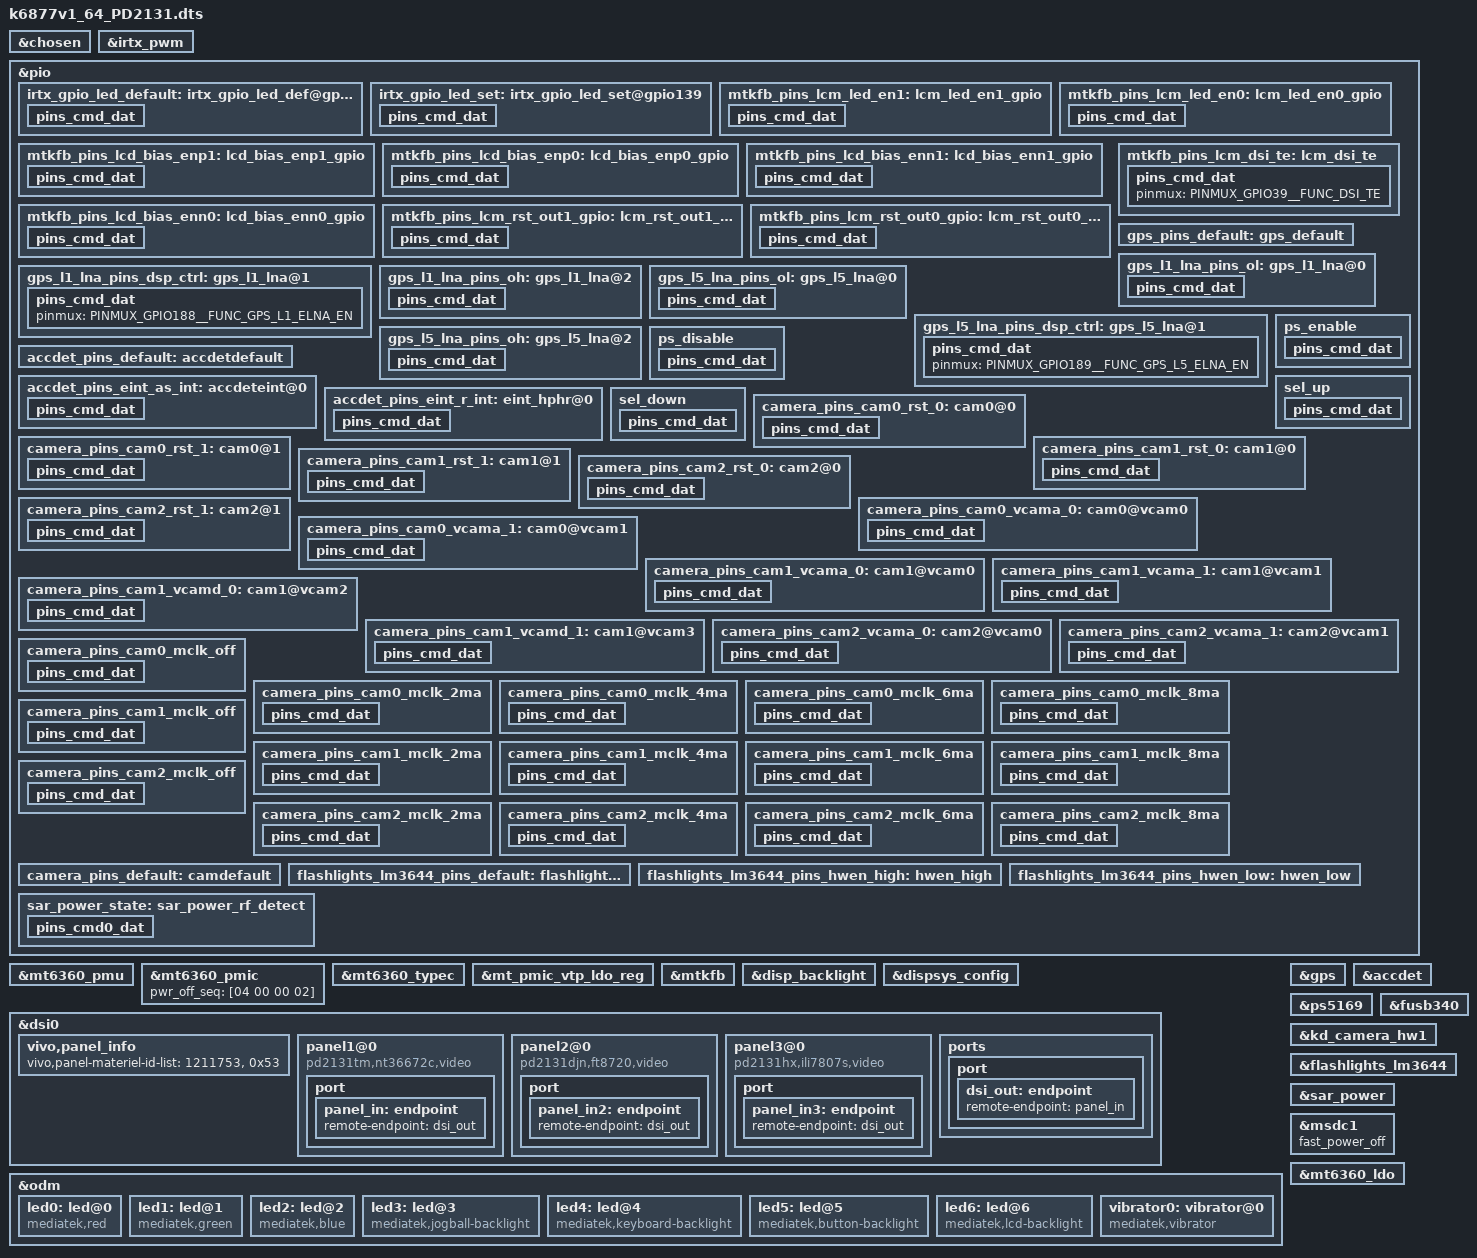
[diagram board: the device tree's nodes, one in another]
/*
 * Mediatek's mt6853 SoC device tree source
 *
 * Copyright (C) 2016 MediaTek Inc.
 *
 * This program is free software; you can redistribute it and/or modify
 * it under the terms of the GNU General Public License version 2 as
 * published by the Free Software Foundation.
 *
 * This program is distributed in the hope that it will be useful,
 * but WITHOUT ANY WARRANTY; without even the implied warranty of
 * MERCHANTABILITY or FITNESS FOR A PARTICULAR PURPOSE.
 * See http://www.gnu.org/licenses/gpl-2.0.html for more details.
 */
/dts-v1/;
/plugin/;
#include <generated/autoconf.h>
#include <dt-bindings/interrupt-controller/irq.h>
#include <dt-bindings/interrupt-controller/arm-gic.h>
#include <dt-bindings/pinctrl/mt6877-pinfunc.h>

/* chosen */
&chosen {
	atag,videolfb-fb_base_l = <0x7e605000>;
	atag,videolfb-fb_base_h = <0x0>;
	atag,videolfb-islcmfound = <1>;
	atag,videolfb-islcm_inited = <0>;
	atag,videolfb-fps= <6000>;
	atag,videolfb-vramSize= <0x1be0000>;
	atag,videolfb-lcmname=
		"td4330_fhdp_dsi_cmd_auo_rt4831_drv";
	atag,videolfb-project-name= "PD2131";
	atag,vivo-dsi-panel-type = "super_tft";
	atag,exception-event-support;
	default-backlight-level = <1146>;
	20ma-brightness-typical-val = <2045>;
	lcd-hbm-support = <1>;
	bias-ic-use-i2c = <3>;
	bl-ic-use-i2c = <3>;
};

/* IRTX GPIO Start */
&irtx_pwm {
	pinctrl-names = "irtx_gpio_led_default", "irtx_gpio_led_set";
	pinctrl-0 = <&irtx_gpio_led_default>;
	pinctrl-1 = <&irtx_gpio_led_set>;
	status = "okay";
};
&pio {
	/* IRTX GPIO Settings -Start */
	/* default: GPIO0, output, high */
	irtx_gpio_led_default:irtx_gpio_led_def@gpio139 {
		pins_cmd_dat {
			pinmux = <PINMUX_GPIO139__FUNC_GPIO139>;
			slew-rate = <1>;
			bias-disable;
			output-low;
			input-schmitt-enable = <0>;
		};
	};

	irtx_gpio_led_set:irtx_gpio_led_set@gpio139 {
		pins_cmd_dat {
			pinmux = <PINMUX_GPIO139__FUNC_PWM_1>;
			slew-rate = <1>;
			output-high;
		};
	};
}; /* IRTX GPIO Settings -End */

&mt6360_pmu {
	mt6360,intr_gpio_num = <4>; /* direct defined GPIO num */
	mt6360,intr_gpio = <&pio 4 0x0>;
};

&mt6360_pmic {
	pwr_off_seq = [04 00 00 02];
};

&mt6360_typec {
	mt6360pd,intr_gpio_num = <5>; /* direct defined GPIO num */
	mt6360pd,intr_gpio = <&pio 5 0x0>;
};

/* add by sensor team for Psensor LED LDO2*/
&mt_pmic_vtp_ldo_reg {
	regulator-min-microvolt = <3000000>;
	regulator-max-microvolt = <3000000>;
	regulator-always-on;
};

&pio {
	mtkfb_pins_lcm_led_en1: lcm_led_en1_gpio {
		pins_cmd_dat {
			pinmux = <PINMUX_GPIO139__FUNC_GPIO139>;
			slew-rate = <1>;
			output-high;
		};
	};

	mtkfb_pins_lcm_led_en0: lcm_led_en0_gpio {
		pins_cmd_dat {
			pinmux = <PINMUX_GPIO139__FUNC_GPIO139>;
			slew-rate = <1>;
			output-low;
		};
	};

	mtkfb_pins_lcd_bias_enp1: lcd_bias_enp1_gpio {
		pins_cmd_dat {
			pinmux = <PINMUX_GPIO141__FUNC_GPIO141>;
			slew-rate = <1>;
			output-high;
		};
	};

	mtkfb_pins_lcd_bias_enp0: lcd_bias_enp0_gpio {
		pins_cmd_dat {
			pinmux = <PINMUX_GPIO141__FUNC_GPIO141>;
			slew-rate = <1>;
			output-low;
		};
	};

	mtkfb_pins_lcd_bias_enn1: lcd_bias_enn1_gpio {
		pins_cmd_dat {
			pinmux = <PINMUX_GPIO140__FUNC_GPIO140>;
			slew-rate = <1>;
			output-high;
		};
	};

	mtkfb_pins_lcd_bias_enn0: lcd_bias_enn0_gpio {
		pins_cmd_dat {
			pinmux = <PINMUX_GPIO140__FUNC_GPIO140>;
			slew-rate = <1>;
			output-low;
		};
	};

	mtkfb_pins_lcm_rst_out1_gpio: lcm_rst_out1_gpio {
		pins_cmd_dat {
			pinmux = <PINMUX_GPIO40__FUNC_GPIO40>;
			slew-rate = <1>;
			output-high;
		};
	};

	mtkfb_pins_lcm_rst_out0_gpio: lcm_rst_out0_gpio {
		pins_cmd_dat {
			pinmux = <PINMUX_GPIO40__FUNC_GPIO40>;
			slew-rate = <1>;
			output-low;
		};
	};
	mtkfb_pins_lcm_dsi_te: lcm_dsi_te {
		pins_cmd_dat {
			pinmux = <PINMUX_GPIO39__FUNC_DSI_TE>;
		};
	};
};

&mtkfb {
	pinctrl-names = "lcm_led_en1_gpio", "lcm_led_en0_gpio",
		"lcd_bias_enp1_gpio", "lcd_bias_enp0_gpio",
		"lcd_bias_enn1_gpio", "lcd_bias_enn0_gpio",
		"lcm_rst_out1_gpio", "lcm_rst_out0_gpio",
		"mode_te_te";
	pinctrl-0 = <&mtkfb_pins_lcm_led_en1>;
	pinctrl-1 = <&mtkfb_pins_lcm_led_en0>;
	pinctrl-2 = <&mtkfb_pins_lcd_bias_enp1>;
	pinctrl-3 = <&mtkfb_pins_lcd_bias_enp0>;
	pinctrl-4 = <&mtkfb_pins_lcd_bias_enn1>;
	pinctrl-5 = <&mtkfb_pins_lcd_bias_enn0>;
	pinctrl-6 = <&mtkfb_pins_lcm_rst_out1_gpio>;
	pinctrl-7 = <&mtkfb_pins_lcm_rst_out0_gpio>;
	pinctrl-8 = <&mtkfb_pins_lcm_dsi_te>;
	status = "okay";
};

&disp_backlight {
	max-brightness = <2047>;
	led-bits = <11>;
};

&dispsys_config {
	pinctrl-names =
		"lcm_rst_out1_gpio", "lcm_rst_out0_gpio",
		"mode_te_te";
	pinctrl-0 = <&mtkfb_pins_lcm_rst_out1_gpio>;
	pinctrl-1 = <&mtkfb_pins_lcm_rst_out0_gpio>;
	pinctrl-2 = <&mtkfb_pins_lcm_dsi_te>;
	status = "okay";

	helper-name = "MTK_DRM_OPT_STAGE",
		"MTK_DRM_OPT_USE_CMDQ",
		"MTK_DRM_OPT_USE_M4U",
		"MTK_DRM_OPT_SODI_SUPPORT",
		"MTK_DRM_OPT_IDLE_MGR",
		"MTK_DRM_OPT_IDLEMGR_SWTCH_DECOUPLE",
		"MTK_DRM_OPT_IDLEMGR_BY_REPAINT",
		"MTK_DRM_OPT_IDLEMGR_ENTER_ULPS",
		"MTK_DRM_OPT_IDLEMGR_KEEP_LP11",
		"MTK_DRM_OPT_DYNAMIC_RDMA_GOLDEN_SETTING",
		"MTK_DRM_OPT_IDLEMGR_DISABLE_ROUTINE_IRQ",
		"MTK_DRM_OPT_MET_LOG",
		"MTK_DRM_OPT_USE_PQ",
		"MTK_DRM_OPT_ESD_CHECK_RECOVERY",
		"MTK_DRM_OPT_ESD_CHECK_SWITCH",
		"MTK_DRM_OPT_PRESENT_FENCE",
		"MTK_DRM_OPT_RDMA_UNDERFLOW_AEE",
		"MTK_DRM_OPT_DSI_UNDERRUN_AEE",
		"MTK_DRM_OPT_HRT",
		"MTK_DRM_OPT_HRT_MODE",
		"MTK_DRM_OPT_DELAYED_TRIGGER",
		"MTK_DRM_OPT_OVL_EXT_LAYER",
		"MTK_DRM_OPT_AOD",
		"MTK_DRM_OPT_RPO",
		"MTK_DRM_OPT_DUAL_PIPE",
		"MTK_DRM_OPT_DC_BY_HRT",
		"MTK_DRM_OPT_OVL_WCG",
		"MTK_DRM_OPT_OVL_SBCH",
		"MTK_DRM_OPT_COMMIT_NO_WAIT_VBLANK",
		"MTK_DRM_OPT_MET",
		"MTK_DRM_OPT_REG_PARSER_RAW_DUMP",
		"MTK_DRM_OPT_VP_PQ",
		"MTK_DRM_OPT_GAME_PQ",
		"MTK_DRM_OPT_MMPATH",
		"MTK_DRM_OPT_HBM",
		"MTK_DRM_OPT_VDS_PATH_SWITCH",
		"MTK_DRM_OPT_LAYER_REC",
		"MTK_DRM_OPT_CLEAR_LAYER",
		"MTK_DRM_OPT_LFR",
		"MTK_DRM_OPT_DYN_MIPI_CHANGE",
		"MTK_DRM_OPT_SF_PF";

		helper-value = <0>, /*MTK_DRM_OPT_STAGE*/
			<1>, /*MTK_DRM_OPT_USE_CMDQ*/
			<1>, /*MTK_DRM_OPT_USE_M4U*/
			<0>, /*MTK_DRM_OPT_SODI_SUPPORT*/
			<1>, /*MTK_DRM_OPT_IDLE_MGR*/
			<0>, /*MTK_DRM_OPT_IDLEMGR_SWTCH_DECOUPLE*/
			<1>, /*MTK_DRM_OPT_IDLEMGR_BY_REPAINT*/
			<0>, /*MTK_DRM_OPT_IDLEMGR_ENTER_ULPS*/
			<0>, /*MTK_DRM_OPT_IDLEMGR_KEEP_LP11*/
			<0>, /*MTK_DRM_OPT_DYNAMIC_RDMA_GOLDEN_SETTING*/
			<1>, /*MTK_DRM_OPT_IDLEMGR_DISABLE_ROUTINE_IRQ*/
			<0>, /*MTK_DRM_OPT_MET_LOG*/
			<1>, /*MTK_DRM_OPT_USE_PQ*/
			<1>, /*MTK_DRM_OPT_ESD_CHECK_RECOVERY*/
			<1>, /*MTK_DRM_OPT_ESD_CHECK_SWITCH*/
			<1>, /*MTK_DRM_OPT_PRESENT_FENCE*/
			<1>, /*MTK_DRM_OPT_RDMA_UNDERFLOW_AEE*/
			<1>, /*MTK_DRM_OPT_DSI_UNDERRUN_AEE*/
			<1>, /*MTK_DRM_OPT_HRT*/
			<1>, /*MTK_DRM_OPT_HRT_MODE*/
			<0>, /*MTK_DRM_OPT_DELAYED_TRIGGER*/
			<1>, /*MTK_DRM_OPT_OVL_EXT_LAYER*/
			<0>, /*MTK_DRM_OPT_AOD*/
			<1>, /*MTK_DRM_OPT_RPO*/
			<0>, /*MTK_DRM_OPT_DUAL_PIPE*/
			<0>, /*MTK_DRM_OPT_DC_BY_HRT*/
			<0>, /*MTK_DRM_OPT_OVL_WCG*/
			<0>, /*MTK_DRM_OPT_OVL_SBCH*/
			<1>, /*MTK_DRM_OPT_COMMIT_NO_WAIT_VBLANK*/
			<0>, /*MTK_DRM_OPT_MET*/
			<0>, /*MTK_DRM_OPT_REG_PARSER_RAW_DUMP*/
			<0>, /*MTK_DRM_OPT_VP_PQ*/
			<0>, /*MTK_DRM_OPT_GAME_PQ*/
			<0>, /*MTK_DRM_OPT_MMPATH*/
			<1>, /*MTK_DRM_OPT_HBM*/
			<0>, /*MTK_DRM_OPT_VDS_PATH_SWITCH*/
			<0>, /*MTK_DRM_OPT_LAYER_REC*/
			<1>, /*MTK_DRM_OPT_CLEAR_LAYER*/
			<0>, /*MTK_DRM_OPT_LFR*/
			<1>, /*MTK_DRM_OPT_DYN_MIPI_CHANGE*/
			<1>; /*MTK_DRM_OPT_SF_PF*/
	};

&dsi0 {
	status = "okay";
	#address-cells = <1>;
	#size-cells = <0>;

	/* vivo panel materiel info start */
	vivo,panel_info {
		/*
		 * No add new id until you have import driver for new panel ok!!!!!!
		 * vivo,panel-materiel-id-list = "materiel_id1", "lcm1_sf_id1 lcm1_sf_id2 lcm1_sf_id3...",
		 *				 "materiel_id2", "lcm2_sf_id1 lcm2_sf_id2 lcm2_sf_id3...",
		 *				 ...
		 *				 "materiel_idX", "lcmX_sf_id1 lcmX_sf_id2 lcmX_sf_id3...";
		 */
		vivo,panel-materiel-id-list = "1211753", "0x53";
	};
	/* vivo panel materiel info end */

	panel1@0 {
		compatible = "pd2131tm,nt36672c,video";
		reg = <0>;
		lcm_backlight_en-gpios = <&pio 139 0>;
		lcm_reset-gpios = <&pio 40 0>;
		lcm_avdd_en-gpios = <&pio 141 0>;
		lcm_avee_en-gpios = <&pio 140 0>;
		//lcm_vddr_en-gpios = <&pio 109 0>;
		tp_reset-gpios = <&pio 15 0>;
		pinctrl-names = "default";
		port {
			panel_in: endpoint {
				remote-endpoint = <&dsi_out>;
			};
		};
	};

	panel2@0 {
		compatible = "pd2131djn,ft8720,video";
		reg = <1>;
		lcm_backlight_en-gpios = <&pio 139 0>;
		lcm_reset-gpios = <&pio 40 0>;
		lcm_avdd_en-gpios = <&pio 141 0>;
		lcm_avee_en-gpios = <&pio 140 0>;
		//lcm_vddr_en-gpios = <&pio 109 0>;
		tp_reset-gpios = <&pio 15 0>;
		pinctrl-names = "default";
		port {
			panel_in2: endpoint {
				remote-endpoint = <&dsi_out>;
			};
		};
	};

	panel3@0 {
		compatible = "pd2131hx,ili7807s,video";
		reg = <2>;
		lcm_backlight_en-gpios = <&pio 139 0>;
		lcm_reset-gpios = <&pio 40 0>;
		lcm_avdd_en-gpios = <&pio 141 0>;
		lcm_avee_en-gpios = <&pio 140 0>;
		//lcm_vddr_en-gpios = <&pio 109 0>;
		tp_reset-gpios = <&pio 15 0>;
		pinctrl-names = "default";
		port {
			panel_in3: endpoint {
				remote-endpoint = <&dsi_out>;
			};
		};
	};
	ports {
		port {
			dsi_out: endpoint {
				remote-endpoint = <&panel_in>;
			};
		};
	};
};

&odm {
	led0:led@0 {
		compatible = "mediatek,red";
		led_mode = <0>;
		data = <1>;
		pwm_config = <0 0 0 0 0>;
	};
	led1:led@1 {
		compatible = "mediatek,green";
		led_mode = <0>;
		data = <1>;
		pwm_config = <0 0 0 0 0>;
	};
	led2:led@2 {
		compatible = "mediatek,blue";
		led_mode = <0>;
		data = <1>;
		pwm_config = <0 0 0 0 0>;
	};
	led3:led@3 {
		compatible = "mediatek,jogball-backlight";
		led_mode = <0>;
		data = <1>;
		pwm_config = <0 0 0 0 0>;
	};
	led4:led@4 {
		compatible = "mediatek,keyboard-backlight";
		led_mode = <0>;
		data = <1>;
		pwm_config = <0 0 0 0 0>;
	};
	led5:led@5 {
		compatible = "mediatek,button-backlight";
		led_mode = <0>;
		data = <1>;
		pwm_config = <0 0 0 0 0>;
	};
	led6:led@6 {
		compatible = "mediatek,lcd-backlight";
		led_mode = <4>;
		data = <1>;
		pwm_config = <0 1023 2045 1600 0>;
	};
	vibrator0:vibrator@0 {
		compatible = "mediatek,vibrator";
		vib_timer = <25>;
		vib_limit = <9>;
		vib_vol= <11>;
	};
};

/* GPS GPIO standardization start */
&pio {
	gps_pins_default: gps_default {
	};
	gps_l1_lna_pins_ol: gps_l1_lna@0 {
		pins_cmd_dat {
			pinmux = <PINMUX_GPIO188__FUNC_GPIO188>;
			output-low;
		};
	};
	gps_l1_lna_pins_dsp_ctrl: gps_l1_lna@1 {
		pins_cmd_dat {
			pinmux = <PINMUX_GPIO188__FUNC_GPS_L1_ELNA_EN>;
		};
	};
	gps_l1_lna_pins_oh: gps_l1_lna@2 {
		pins_cmd_dat {
			pinmux = <PINMUX_GPIO188__FUNC_GPIO188>;
			output-high;
		};
	};
	gps_l5_lna_pins_ol: gps_l5_lna@0 {
		pins_cmd_dat {
			pinmux = <PINMUX_GPIO189__FUNC_GPIO189>;
			output-low;
		};
	};
	gps_l5_lna_pins_dsp_ctrl: gps_l5_lna@1 {
		pins_cmd_dat {
			pinmux = <PINMUX_GPIO189__FUNC_GPS_L5_ELNA_EN>;
		};
	};
	gps_l5_lna_pins_oh: gps_l5_lna@2 {
		pins_cmd_dat {
			pinmux = <PINMUX_GPIO189__FUNC_GPIO189>;
			output-high;
		};
	};
};
&gps {
	pinctrl-names = "default",
		"gps_l1_lna_disable",
		"gps_l1_lna_dsp_ctrl",
		"gps_l1_lna_enable",
		"gps_l5_lna_disable",
		"gps_l5_lna_dsp_ctrl",
		"gps_l5_lna_enable";
	pinctrl-0 = <&gps_pins_default>;
	pinctrl-1 = <&gps_l1_lna_pins_ol>;
	pinctrl-2 = <&gps_l1_lna_pins_dsp_ctrl>;
	pinctrl-3 = <&gps_l1_lna_pins_oh>;
	pinctrl-4 = <&gps_l5_lna_pins_ol>;
	pinctrl-5 = <&gps_l5_lna_pins_dsp_ctrl>;
	pinctrl-6 = <&gps_l5_lna_pins_oh>;
	status = "okay";
};
/* GPS GPIO standardization end */

&accdet {
	/* accdet micbias voltage: 0x09:2.85v 0x08:2.8v 0x07,
	 * 2.7v;0x05,2.5v;0x02,1.9v
	 */
	accdet-mic-vol = <7>;
	/* accdet pwm_width, pwm_thresh, fall_delay, rise_delay
	 * debounce0, debounce1, debounce3, debounce4
	 * eint pwm_width, eint pwm_thresh
	 * eint deb(debounce0, debounce1, debounce2, debounce3), inv_debounce
	 */
	headset-mode-setting = <0x500 0x500 1 0x1f0
				0x800 0x800 0x20 0x44
				0x4 0x1
				0x5 0x3 0x3 0x5 0xe>;
	accdet-plugout-debounce = <16>;
	/*1:ACC mode, 2:low cost without in bias, 6:low cost with in bias*/
	accdet-mic-mode = <2>;
	/*0--MD_MAX--UP_MAX--DW_MAX*/
	headset-three-key-threshold = <0 90 210 430>;
	headset-three-key-threshold-CDD = <0 121 192 600>;
	/*0--MD_MAX--VOICE_MAX--UP_MAX--DW_MAX*/
	headset-four-key-threshold = <0 60 106 210 430>;

	/* select VTH to 2v and 500k, use internal resitance */
	eint_use_ext_res = <0>;
	pinctrl-names = "default", "state_eint_as_int", "state_eint_r_as_int";
	pinctrl-0 = <&accdet_pins_default>;
	pinctrl-1 = <&accdet_pins_eint_as_int>;
	pinctrl-2 = <&accdet_pins_eint_r_int>;
	status = "okay";
};

&pio {
	accdet_pins_default: accdetdefault {
	};
	accdet_pins_eint_as_int: accdeteint@0 {
		pins_cmd_dat {
			pinmux = <PINMUX_GPIO17__FUNC_GPIO17>;
			slew-rate = <0>;
			bias-disable;
		};
	};
	accdet_pins_eint_r_int: eint_hphr@0 {
		pins_cmd_dat {
			pinmux = <PINMUX_GPIO16__FUNC_GPIO16>;
			slew-rate = <0>;
			bias-disable;
		};
	};
};

/* accdet end */

&ps5169{
	pinctrl-names = "enable", "disable";
	pinctrl-0 = <&ps_enable>;
	pinctrl-1 = <&ps_disable>;
	status = "okay";
};

&fusb340 {
	pinctrl-names = "sel_up", "sel_down";
	pinctrl-0 = <&sel_up>;
	pinctrl-1 = <&sel_down>;
	status = "okay";
};

&pio {
	ps_enable: ps_enable {
		pins_cmd_dat {
			pinmux = <PINMUX_GPIO121__FUNC_GPIO121>;
			output-high;
		};
	};

	ps_disable: ps_disable {
		pins_cmd_dat {
			pinmux = <PINMUX_GPIO121__FUNC_GPIO121>;
			output-low;
		};
	};

	sel_up: sel_up {
		pins_cmd_dat {
			pinmux = <PINMUX_GPIO6__FUNC_GPIO6>;
			output-low;
		};
	};

	sel_down: sel_down {
		pins_cmd_dat {
			pinmux = <PINMUX_GPIO6__FUNC_GPIO6>;
			output-high;
		};
	};
};

/* CAMERA GPIO standardization */
&pio {
	camera_pins_cam0_rst_0: cam0@0 {
		pins_cmd_dat {
			pinmux = <PINMUX_GPIO155__FUNC_GPIO155>;
			slew-rate = <1>;
			output-low;
		};
	};
	camera_pins_cam0_rst_1: cam0@1 {
		pins_cmd_dat {
			pinmux = <PINMUX_GPIO155__FUNC_GPIO155>;
			slew-rate = <1>;
			output-high;
		};
	};
	camera_pins_cam1_rst_0: cam1@0 {
		pins_cmd_dat {
			pinmux = <PINMUX_GPIO157__FUNC_GPIO157>;
			slew-rate = <1>;
			output-low;
		};
	};
	camera_pins_cam1_rst_1: cam1@1 {
		pins_cmd_dat {
			pinmux = <PINMUX_GPIO157__FUNC_GPIO157>;
			slew-rate = <1>;
			output-high;
		};
	};
	camera_pins_cam2_rst_0: cam2@0 {
		pins_cmd_dat {
			pinmux = <PINMUX_GPIO163__FUNC_GPIO163>;
			slew-rate = <1>;
			output-low;
		};
	};
	camera_pins_cam2_rst_1: cam2@1 {
		pins_cmd_dat {
			pinmux = <PINMUX_GPIO163__FUNC_GPIO163>;
			slew-rate = <1>;
			output-high;
		};
	};

/*main power start*/
	camera_pins_cam0_vcama_0: cam0@vcam0 {
		pins_cmd_dat {
			pinmux = <PINMUX_GPIO154__FUNC_GPIO154>;
			slew-rate = <1>;
			output-low;
		};
	};
	camera_pins_cam0_vcama_1: cam0@vcam1 {
		pins_cmd_dat {
			pinmux = <PINMUX_GPIO154__FUNC_GPIO154>;
			slew-rate = <1>;
			output-high;
		};
	};
/*main power end*/

/*sub power start*/
	camera_pins_cam1_vcama_0: cam1@vcam0 {
		pins_cmd_dat {
			pinmux = <PINMUX_GPIO154__FUNC_GPIO154>;
			slew-rate = <1>;
			output-low;
		};
	};
	camera_pins_cam1_vcama_1: cam1@vcam1 {
		pins_cmd_dat {
			pinmux = <PINMUX_GPIO154__FUNC_GPIO154>;
			slew-rate = <1>;
			output-high;
		};
	};
	
	camera_pins_cam1_vcamd_0: cam1@vcam2 {
		pins_cmd_dat {
			pinmux = <PINMUX_GPIO160__FUNC_GPIO160>;
			slew-rate = <1>;
			output-low;
		};
	};
	camera_pins_cam1_vcamd_1: cam1@vcam3 {
		pins_cmd_dat {
			pinmux = <PINMUX_GPIO160__FUNC_GPIO160>;
			slew-rate = <1>;
			output-high;
		};
	};	
/*sub power end*/

/*main2 power start*/
	camera_pins_cam2_vcama_0: cam2@vcam0 {
		pins_cmd_dat {
			pinmux = <PINMUX_GPIO154__FUNC_GPIO154>;
			slew-rate = <1>;
			output-low;
		};
	};
	camera_pins_cam2_vcama_1: cam2@vcam1 {
		pins_cmd_dat {
			pinmux = <PINMUX_GPIO154__FUNC_GPIO154>;
			slew-rate = <1>;
			output-high;
		};
	};
/*main2 power end*/


	camera_pins_cam0_mclk_off: camera_pins_cam0_mclk_off {
		pins_cmd_dat {
			pinmux = <PINMUX_GPIO149__FUNC_GPIO149>;
			drive-strength = <1>;
		};
	};
	camera_pins_cam0_mclk_2ma: camera_pins_cam0_mclk_2ma {
		pins_cmd_dat {
			pinmux = <PINMUX_GPIO149__FUNC_CMMCLK0>;
			drive-strength = <0>;
		};
	};
	camera_pins_cam0_mclk_4ma: camera_pins_cam0_mclk_4ma {
		pins_cmd_dat {
			pinmux = <PINMUX_GPIO149__FUNC_CMMCLK0>;
			drive-strength = <1>;
		};
	};
	camera_pins_cam0_mclk_6ma: camera_pins_cam0_mclk_6ma {
		pins_cmd_dat {
			pinmux = <PINMUX_GPIO149__FUNC_CMMCLK0>;
			drive-strength = <2>;
		};
	};
	camera_pins_cam0_mclk_8ma: camera_pins_cam0_mclk_8ma {
		pins_cmd_dat {
			pinmux = <PINMUX_GPIO149__FUNC_CMMCLK0>;
			drive-strength = <3>;
		};
	};

	camera_pins_cam1_mclk_off: camera_pins_cam1_mclk_off {
		pins_cmd_dat {
			pinmux = <PINMUX_GPIO150__FUNC_GPIO150>;
			drive-strength = <1>;
		};
	};
	camera_pins_cam1_mclk_2ma: camera_pins_cam1_mclk_2ma {
		pins_cmd_dat {
			pinmux = <PINMUX_GPIO150__FUNC_CMMCLK1>;
			drive-strength = <0>;
		};
	};
	camera_pins_cam1_mclk_4ma: camera_pins_cam1_mclk_4ma {
		pins_cmd_dat {
			pinmux = <PINMUX_GPIO150__FUNC_CMMCLK1>;
			drive-strength = <1>;
		};
	};
	camera_pins_cam1_mclk_6ma: camera_pins_cam1_mclk_6ma {
		pins_cmd_dat {
			pinmux = <PINMUX_GPIO150__FUNC_CMMCLK1>;
			drive-strength = <2>;
		};
	};
	camera_pins_cam1_mclk_8ma: camera_pins_cam1_mclk_8ma {
		pins_cmd_dat {
			pinmux = <PINMUX_GPIO150__FUNC_CMMCLK1>;
			drive-strength = <3>;
		};
	};


	camera_pins_cam2_mclk_off: camera_pins_cam2_mclk_off {
		pins_cmd_dat {
			pinmux = <PINMUX_GPIO152__FUNC_GPIO152>;
			drive-strength = <1>;
		};
	};
	camera_pins_cam2_mclk_2ma: camera_pins_cam2_mclk_2ma {
		pins_cmd_dat {
			pinmux = <PINMUX_GPIO152__FUNC_CMMCLK3>;
			drive-strength = <0>;
		};
	};
	camera_pins_cam2_mclk_4ma: camera_pins_cam2_mclk_4ma {
		pins_cmd_dat {
			pinmux = <PINMUX_GPIO152__FUNC_CMMCLK3>;
			drive-strength = <1>;
		};
	};
	camera_pins_cam2_mclk_6ma: camera_pins_cam2_mclk_6ma {
		pins_cmd_dat {
			pinmux = <PINMUX_GPIO152__FUNC_CMMCLK3>;
			drive-strength = <2>;
		};
	};
	camera_pins_cam2_mclk_8ma: camera_pins_cam2_mclk_8ma {
		pins_cmd_dat {
			pinmux = <PINMUX_GPIO152__FUNC_CMMCLK3>;
			drive-strength = <3>;
		};
	};

	camera_pins_default: camdefault {
	};
};

&kd_camera_hw1 {
	pinctrl-names = "default",
			"cam0_rst0", "cam0_rst1",
			"cam1_rst0", "cam1_rst1",
			"cam2_rst0", "cam2_rst1",
			"cam0_mclk_off",
			"cam0_mclk_2mA", "cam0_mclk_4mA",
			"cam0_mclk_6mA", "cam0_mclk_8mA",
			"cam1_mclk_off",
			"cam1_mclk_2mA", "cam1_mclk_4mA",
			"cam1_mclk_6mA", "cam1_mclk_8mA",
			"cam2_mclk_off",
			"cam2_mclk_2mA", "cam2_mclk_4mA",
			"cam2_mclk_6mA", "cam2_mclk_8mA",
			"cam0_ldo_vcama_0","cam0_ldo_vcama_1",
			"cam1_ldo_vcama_0","cam1_ldo_vcama_1",
			"cam1_ldo_vcamd_0","cam1_ldo_vcamd_1",
			"cam2_ldo_vcama_0","cam2_ldo_vcama_1";
			
	pinctrl-0 = <&camera_pins_default>;
	pinctrl-1 = <&camera_pins_cam0_rst_0>;
	pinctrl-2 = <&camera_pins_cam0_rst_1>;
	pinctrl-3 = <&camera_pins_cam1_rst_0>;
	pinctrl-4 = <&camera_pins_cam1_rst_1>;
	pinctrl-5 = <&camera_pins_cam2_rst_0>;
	pinctrl-6 = <&camera_pins_cam2_rst_1>;
	pinctrl-7 = <&camera_pins_cam0_mclk_off>;
	pinctrl-8 = <&camera_pins_cam0_mclk_2ma>;
	pinctrl-9 = <&camera_pins_cam0_mclk_4ma>;
	pinctrl-10 = <&camera_pins_cam0_mclk_6ma>;
	pinctrl-11 = <&camera_pins_cam0_mclk_8ma>;
	pinctrl-12 = <&camera_pins_cam1_mclk_off>;
	pinctrl-13 = <&camera_pins_cam1_mclk_2ma>;
	pinctrl-14 = <&camera_pins_cam1_mclk_4ma>;
	pinctrl-15 = <&camera_pins_cam1_mclk_6ma>;
	pinctrl-16 = <&camera_pins_cam1_mclk_8ma>;
	pinctrl-17 = <&camera_pins_cam2_mclk_off>;
	pinctrl-18 = <&camera_pins_cam2_mclk_2ma>;
	pinctrl-19 = <&camera_pins_cam2_mclk_4ma>;
	pinctrl-20 = <&camera_pins_cam2_mclk_6ma>;
	pinctrl-21 = <&camera_pins_cam2_mclk_8ma>;
	pinctrl-22 = <&camera_pins_cam0_vcama_0>; 
	pinctrl-23 = <&camera_pins_cam0_vcama_1>;
	pinctrl-24 = <&camera_pins_cam1_vcama_0>;
	pinctrl-25 = <&camera_pins_cam1_vcama_1>;
	pinctrl-26 = <&camera_pins_cam1_vcamd_0>;
	pinctrl-27 = <&camera_pins_cam1_vcamd_1>;
	pinctrl-28 = <&camera_pins_cam2_vcama_0>;
	pinctrl-29 = <&camera_pins_cam2_vcama_1>;
	status = "okay";
};

/* CAMERA GPIO end */



/* FLASHLIGHT START*/
&pio {
	flashlights_lm3644_pins_default: flashlight_default {
	};

	flashlights_lm3644_pins_hwen_high: hwen_high {
	};

	flashlights_lm3644_pins_hwen_low: hwen_low {
	};
};

&flashlights_lm3644 {
	pinctrl-names = "default", "hwen_high", "hwen_low" ;
	pinctrl-0 = <&flashlights_lm3644_pins_default>;
	pinctrl-1 = <&flashlights_lm3644_pins_hwen_high>;
	pinctrl-2 = <&flashlights_lm3644_pins_hwen_low>;
	status = "okay";
};
/* FLASHLIGHT END*/

/* ADD by vsensor team for SAR Power */
&pio {
	sar_power_state: sar_power_rf_detect {
		pins_cmd0_dat {
			pinmux = <PINMUX_GPIO28__FUNC_GPIO28>,<PINMUX_GPIO29__FUNC_GPIO29>,<PINMUX_GPIO30__FUNC_GPIO30>,<PINMUX_GPIO31__FUNC_GPIO31>;
			slew-rate = <0>;
			bias-disable;
		};
	};
};

&sar_power {
	status="okay";
	pinctrl-names = "default";
	pinctrl-0 = <&sar_power_state>;
	sar-power-rf-detect,gpios= <&pio 28 0x0>;
	sar-power-rf-detect_1,gpios= <&pio 29 0x0>;
	sar-power-rf-detect_2,gpios= <&pio 30 0x0>;
	sar-power-rf-detect_3,gpios= <&pio 31 0x0>;
};
/* ADD by vsensor team for SAR Power */
/* yangtao add for tf start */
&msdc1 {
	fast_power_off;
};

&mt6360_ldo {
	sdcard_det_en = <1>;
	sdcard_hlact = <0>;
};
/* yangtao add for tf end */

/* #include <k6877v1_64/cust.dtsi> */
#include "mediatek/cust_vivo_PD2131.dtsi"
#include "mediatek/vivo_tp_setting/mtk-vivo-tp-PD2131.dtsi"
#include "mediatek/fingerprint/mtk6877-vivo-fp-PD2131.dtsi"
/*#include "mediatek/cust_mt6877_camera.dtsi"*/
/*End of this file, DO NOT ADD ANYTHING HERE*/

